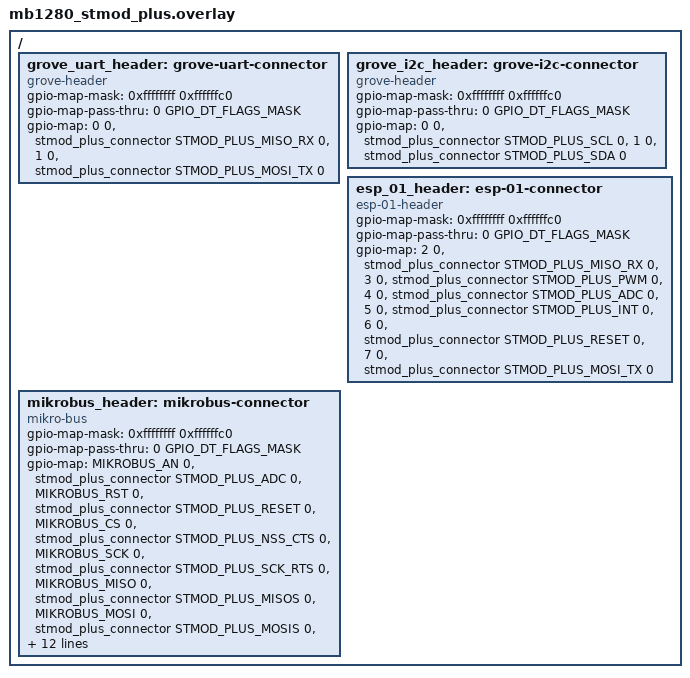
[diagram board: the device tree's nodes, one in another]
/*
 * SPDX-FileCopyrightText: Copyright The Zephyr Project Contributors
 *
 * SPDX-License-Identifier: Apache-2.0
 */

#include <zephyr/dt-bindings/gpio/gpio.h>
#include <zephyr/dt-bindings/gpio/mikro-bus.h>
#include <zephyr/dt-bindings/gpio/stmod-plus-connector.h>

/ {
	grove_uart_header: grove-uart-connector {
		compatible = "grove-header";
		#gpio-cells = <2>;
		gpio-map-mask = <0xffffffff 0xffffffc0>;
		gpio-map-pass-thru = <0 GPIO_DT_FLAGS_MASK>;
		gpio-map = <0 0 &stmod_plus_connector STMOD_PLUS_MISO_RX 0>, /* RX */
			   <1 0 &stmod_plus_connector STMOD_PLUS_MOSI_TX 0>; /* TX */
	};

	grove_i2c_header: grove-i2c-connector {
		compatible = "grove-header";
		#gpio-cells = <2>;
		gpio-map-mask = <0xffffffff 0xffffffc0>;
		gpio-map-pass-thru = <0 GPIO_DT_FLAGS_MASK>;
		gpio-map = <0 0 &stmod_plus_connector STMOD_PLUS_SCL 0>, /* SCL */
			   <1 0 &stmod_plus_connector STMOD_PLUS_SDA 0>; /* SDA */
	};

	esp_01_header: esp-01-connector {
		compatible = "esp-01-header";
		#gpio-cells = <2>;
		gpio-map-mask = <0xffffffff 0xffffffc0>;
		gpio-map-pass-thru = <0 GPIO_DT_FLAGS_MASK>;
		gpio-map = <2 0 &stmod_plus_connector STMOD_PLUS_MISO_RX 0>, /* RXD */
			   <3 0 &stmod_plus_connector STMOD_PLUS_PWM 0>,     /* GPIO2 */
			   <4 0 &stmod_plus_connector STMOD_PLUS_ADC 0>,     /* CH_PD */
			   <5 0 &stmod_plus_connector STMOD_PLUS_INT 0>,     /* GPIO0 */
			   <6 0 &stmod_plus_connector STMOD_PLUS_RESET 0>,   /* RST */
			   <7 0 &stmod_plus_connector STMOD_PLUS_MOSI_TX 0>; /* TXD */
	};

	mikrobus_header: mikrobus-connector {
		compatible = "mikro-bus";
		#gpio-cells = <2>;
		gpio-map-mask = <0xffffffff 0xffffffc0>;
		gpio-map-pass-thru = <0 GPIO_DT_FLAGS_MASK>;
		gpio-map = <MIKROBUS_AN 0 &stmod_plus_connector STMOD_PLUS_ADC 0>,
			   <MIKROBUS_RST 0 &stmod_plus_connector STMOD_PLUS_RESET 0>,
			   <MIKROBUS_CS 0 &stmod_plus_connector STMOD_PLUS_NSS_CTS 0>,
			   <MIKROBUS_SCK 0 &stmod_plus_connector STMOD_PLUS_SCK_RTS 0>,
			   <MIKROBUS_MISO 0 &stmod_plus_connector STMOD_PLUS_MISOS 0>,
			   <MIKROBUS_MOSI 0 &stmod_plus_connector STMOD_PLUS_MOSIS 0>,
			   <MIKROBUS_PWM 0 &stmod_plus_connector STMOD_PLUS_PWM 0>,
			   <MIKROBUS_INT 0 &stmod_plus_connector STMOD_PLUS_INT 0>,
			   <MIKROBUS_RX 0 &stmod_plus_connector STMOD_PLUS_MISO_RX 0>,
			   <MIKROBUS_TX 0 &stmod_plus_connector STMOD_PLUS_MOSI_TX 0>,
			   <MIKROBUS_SCL 0 &stmod_plus_connector STMOD_PLUS_SCL 0>,
			   <MIKROBUS_SDA 0 &stmod_plus_connector STMOD_PLUS_SDA 0>;
	};
};
